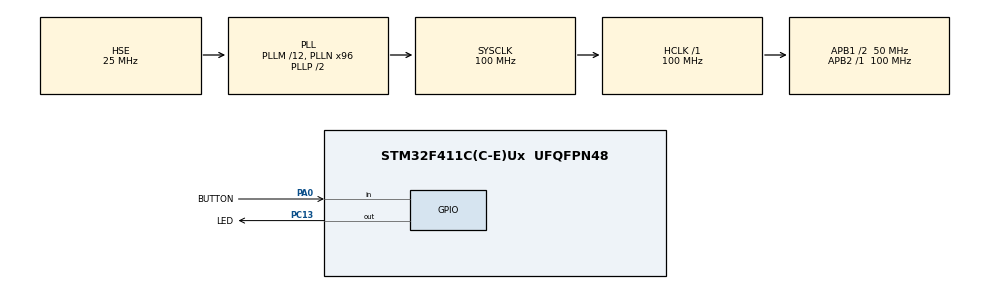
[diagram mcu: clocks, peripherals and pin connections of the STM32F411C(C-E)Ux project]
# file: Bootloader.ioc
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Mcu.Family=STM32F4
Mcu.Name=STM32F411C(C-E)Ux
Mcu.Package=UFQFPN48
NVIC.PriorityGroup=NVIC_PRIORITYGROUP_4
PA0-WKUP.GPIO_Label=BUTTON
PA0-WKUP.GPIO_PuPd=GPIO_PULLUP
PA0-WKUP.Signal=GPIO_Input
PA13.Mode=Serial_Wire
PA13.Signal=SYS_JTMS-SWDIO
PA14.Mode=Serial_Wire
PA14.Signal=SYS_JTCK-SWCLK
PC13-ANTI_TAMP.GPIO_Label=LED
PC13-ANTI_TAMP.Signal=GPIO_Output
PH0\ -\ OSC_IN.Mode=HSE-External-Oscillator
PH0\ -\ OSC_IN.Signal=RCC_OSC_IN
PH1\ -\ OSC_OUT.Mode=HSE-External-Oscillator
PH1\ -\ OSC_OUT.Signal=RCC_OSC_OUT
ProjectManager.HeapSize=0x200
ProjectManager.StackSize=0x400
ProjectManager.TargetToolchain=STM32CubeIDE
RCC.48MHZClocksFreq_Value=50000000
RCC.AHBFreq_Value=100000000
RCC.APB1CLKDivider=RCC_HCLK_DIV2
RCC.APB1Freq_Value=50000000
RCC.APB1TimFreq_Value=100000000
RCC.APB2Freq_Value=100000000
RCC.APB2TimFreq_Value=100000000
RCC.CortexFreq_Value=100000000
RCC.HCLKFreq_Value=100000000
RCC.HSE_VALUE=25000000
RCC.HSI_VALUE=16000000
RCC.LSE_VALUE=32768
RCC.PLLM=12
RCC.PLLN=96
RCC.PLLSourceVirtual=RCC_PLLSOURCE_HSE
RCC.SYSCLKFreq_VALUE=100000000
RCC.SYSCLKSource=RCC_SYSCLKSOURCE_PLLCLK
RCC.VCOOutputFreq_Value=200000000
board=custom

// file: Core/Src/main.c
/* USER CODE BEGIN Header */
/**
  ******************************************************************************
  * @file           : main.c
  * @brief          : Main program body
  ******************************************************************************
  * @attention
  *
  * Copyright (c) 2026 STMicroelectronics.
  * All rights reserved.
  *
  * This software is licensed under terms that can be found in the LICENSE file
  * in the root directory of this software component.
  * If no LICENSE file comes with this software, it is provided AS-IS.
  *
  ******************************************************************************
  */
/* USER CODE END Header */
#include "main.h"
#include "gpio.h"

void SystemClock_Config(void);

/* USER CODE BEGIN 0 */

typedef void (*pFunction)(void); // Define a function pointer type

void JumpToApplication(void)
{
  uint32_t AppAddress = 0x08004000;

  // 1. Check if there is a valid application written at 0x08004000
  // The first 4 bytes of an app are always the Initial Stack Pointer (MSP).
  // We check if the stack pointer points to valid RAM (0x20000000 to 0x20020000).
  if (((*(__IO uint32_t*)AppAddress) & 0x2FFC0000) == 0x20000000)
  {
    // 2. De-initialize hardware peripherals so they don't interfere with the App
    HAL_RCC_DeInit();
    SysTick->CTRL = 0; // Disable SysTick Timer
    SCB->ICSR = SCB_ICSR_PENDSTCLR_Msk; // Clear pending SysTick interrupt

    // 3. Disable all interrupts
    __disable_irq();

    // 4. Set the Main Stack Pointer (MSP) to the App's stack pointer
    __set_MSP(*(__IO uint32_t*)AppAddress);

    // 5. Set the Vector Table Offset to the App's vector table
    SCB->VTOR = AppAddress;

    // 6. Get the App's Reset Handler address (located 4 bytes after the MSP)
    uint32_t AppResetHandler = *(__IO uint32_t*)(AppAddress + 4);

    // 7. Create a function pointer to the App's Reset Handler
    pFunction Jump = (pFunction)AppResetHandler;

    // 8. Jump to the App!
    Jump();

    // Code should never reach here
    while(1) {}
  }
}

/* USER CODE END 0 */

int main(void)
{

  /* MCU Configuration--------------------------------------------------------*/

  /* Reset of all peripherals, Initializes the Flash interface and the Systick. */
  HAL_Init();

  /* Configure the system clock */
  SystemClock_Config();

  /* Initialize all configured peripherals */
  MX_GPIO_Init();

  /* Infinite loop */
  while (1)
  {

	    /* USER CODE BEGIN 3 */
	    // Check if the BUTTON (PA0) is pressed (Active-High because of Pull-down)
	    if (HAL_GPIO_ReadPin(BUTTON_GPIO_Port, BUTTON_Pin) == GPIO_PIN_SET)
	    {
	      // Button is pressed! Fast blink (Bootloader Mode)
	      HAL_GPIO_TogglePin(LED_GPIO_Port, LED_Pin);
	      HAL_Delay(100);
	    }
	    else
	    {
	      // Button is not pressed. Jump to the Application!
	      HAL_Delay(100);
	      JumpToApplication();

	      // If the jump fails, turn LED ON and hang forever
	      while(1)
	      {
	        HAL_GPIO_WritePin(LED_GPIO_Port, LED_Pin, GPIO_PIN_RESET); // LED ON
	      }
	    }
  }
  /* USER CODE END 3 */
}

void SystemClock_Config(void)
{
  RCC_OscInitTypeDef RCC_OscInitStruct = {0};
  RCC_ClkInitTypeDef RCC_ClkInitStruct = {0};

  /** Configure the main internal regulator output voltage
  */
  __HAL_RCC_PWR_CLK_ENABLE();
  __HAL_PWR_VOLTAGESCALING_CONFIG(PWR_REGULATOR_VOLTAGE_SCALE1);

  /** Initializes the RCC Oscillators according to the specified parameters
  * in the RCC_OscInitTypeDef structure.
  */
  RCC_OscInitStruct.OscillatorType = RCC_OSCILLATORTYPE_HSE;
  RCC_OscInitStruct.HSEState = RCC_HSE_ON;
  RCC_OscInitStruct.PLL.PLLState = RCC_PLL_ON;
  RCC_OscInitStruct.PLL.PLLSource = RCC_PLLSOURCE_HSE;
  RCC_OscInitStruct.PLL.PLLM = 12;
  RCC_OscInitStruct.PLL.PLLN = 96;
  RCC_OscInitStruct.PLL.PLLP = RCC_PLLP_DIV2;
  RCC_OscInitStruct.PLL.PLLQ = 4;
  if (HAL_RCC_OscConfig(&RCC_OscInitStruct) != HAL_OK)
  {
    Error_Handler();
  }

  /** Initializes the CPU, AHB and APB buses clocks
  */
  RCC_ClkInitStruct.ClockType = RCC_CLOCKTYPE_HCLK|RCC_CLOCKTYPE_SYSCLK
                              |RCC_CLOCKTYPE_PCLK1|RCC_CLOCKTYPE_PCLK2;
  RCC_ClkInitStruct.SYSCLKSource = RCC_SYSCLKSOURCE_PLLCLK;
  RCC_ClkInitStruct.AHBCLKDivider = RCC_SYSCLK_DIV1;
  RCC_ClkInitStruct.APB1CLKDivider = RCC_HCLK_DIV2;
  RCC_ClkInitStruct.APB2CLKDivider = RCC_HCLK_DIV1;

  if (HAL_RCC_ClockConfig(&RCC_ClkInitStruct, FLASH_LATENCY_3) != HAL_OK)
  {
    Error_Handler();
  }
}

void Error_Handler(void)
{
  __disable_irq();
  while (1)
  {
  }
}
